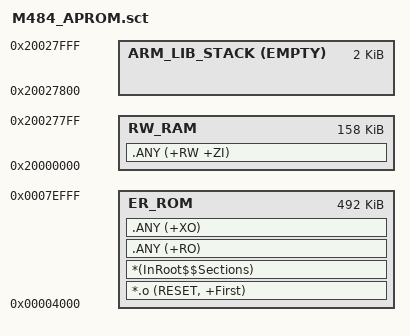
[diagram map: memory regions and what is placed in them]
#! armclang -E --target=arm-arm-none-eabi -mcpu=cortex-m4 -xc
; The first line is required by the Arm scatter-file preprocessor.

#define FLASH_BASE       0x00004000
#define FLASH_SIZE       0x0007B000
#define SRAM_BASE        0x20000000
#define SRAM_SIZE        0x00028000
#define STACK_SIZE       0x00000800
#define HEAP_SIZE        0x00000000

#define STACK_TOP        (SRAM_BASE + SRAM_SIZE)
#define RW_SIZE          (SRAM_SIZE - STACK_SIZE - HEAP_SIZE)
#define HEAP_BASE        (AlignExpr(+0, 8))

LR_ROM FLASH_BASE FLASH_SIZE
{
    ER_ROM FLASH_BASE FLASH_SIZE
    {
        *.o (RESET, +First)
        *(InRoot$$Sections)
        .ANY (+RO)
        .ANY (+XO)
    }

    RW_RAM SRAM_BASE RW_SIZE
    {
        .ANY (+RW +ZI)
    }

#if HEAP_SIZE > 0
    ARM_LIB_HEAP HEAP_BASE EMPTY HEAP_SIZE
    {
    }
#endif

    ARM_LIB_STACK STACK_TOP EMPTY -STACK_SIZE
    {
    }
}
